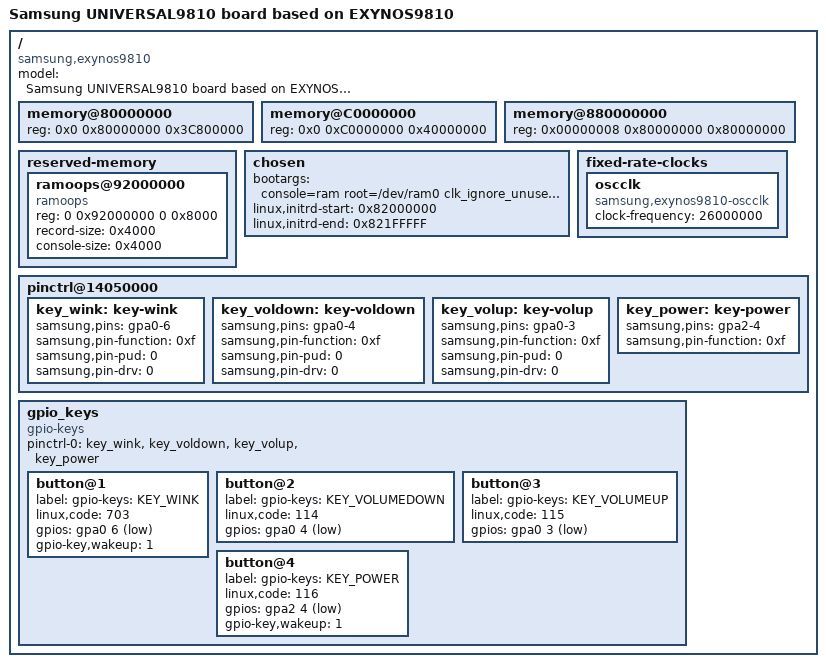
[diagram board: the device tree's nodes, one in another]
/*
 * SAMSUNG EXYNOS9810 board device tree source
 *
 * Copyright (c) 2017 Samsung Electronics Co., Ltd.
 *		http://www.samsung.com
 *
 * This program is free software; you can redistribute it and/or modify
 * it under the terms of the GNU General Public License version 2 as
 * published by the Free Software Foundation.
*/

#include "exynos9810.dtsi"

/ {
	model = "Samsung UNIVERSAL9810 board based on EXYNOS9810";
	compatible = "samsung,exynos9810", "samsung,UNIVERSAL9810";

	memory@80000000 {
		device_type = "memory";
		reg = <0x0 0x80000000 0x3C800000>;
	};

	memory@C0000000 {
		device_type = "memory";
		reg = <0x0 0xC0000000 0x40000000>;
	};

	memory@880000000 {
		device_type = "memory";
		reg = <0x00000008 0x80000000 0x80000000>;
	};

	reserved-memory {
		#address-cells = <2>;
		#size-cells = <2>;
		ranges;

		ramoops@92000000 {
			compatible = "ramoops";
			reg = <0 0x92000000 0 0x8000>;
			record-size = <0x4000>;
			console-size = <0x4000>;
		};
	};

	chosen {
		bootargs = "console=ram root=/dev/ram0 clk_ignore_unused androidboot.hardware=samsungexynos9810";
		linux,initrd-start = <0x82000000>;
		linux,initrd-end = <0x821FFFFF>;
	};

	fixed-rate-clocks {
		oscclk {
			compatible = "samsung,exynos9810-oscclk";
			clock-frequency = <26000000>;
		};
	};

	pinctrl@14050000 {
		key_wink: key-wink {
			samsung,pins = "gpa0-6";
			samsung,pin-function = <0xf>;
			samsung,pin-pud = <0>;
			samsung,pin-drv = <0>;
		};

		key_voldown: key-voldown {
			samsung,pins = "gpa0-4";
			samsung,pin-function = <0xf>;
			samsung,pin-pud = <0>;
			samsung,pin-drv = <0>;
		};

		key_volup: key-volup {
			samsung,pins = "gpa0-3";
			samsung,pin-function = <0xf>;
			samsung,pin-pud = <0>;
			samsung,pin-drv = <0>;
		};

		key_power: key-power {
			samsung,pins = "gpa2-4";
			samsung,pin-function = <0xf>;
		};
	};

	gpio_keys {
		status = "okay";
		compatible = "gpio-keys";
		#address-cells = <1>;
		#size-cells = <0>;
		pinctrl-names = "default";
		pinctrl-0 = <&key_wink &key_voldown &key_volup &key_power>;
		button@1 {
			label = "gpio-keys: KEY_WINK";
			linux,code = <703>;
			gpios = <&gpa0 6 0xf>;
			gpio-key,wakeup = <1>;
		};
		button@2 {
			label = "gpio-keys: KEY_VOLUMEDOWN";
			linux,code = <114>;
			gpios = <&gpa0 4 0xf>;
		};
		button@3 {
			label = "gpio-keys: KEY_VOLUMEUP";
			linux,code = <115>;
			gpios = <&gpa0 3 0xf>;
		};
		button@4 {
			label = "gpio-keys: KEY_POWER";
			linux,code = <116>;
			gpios = <&gpa2 4 0xf>;
			gpio-key,wakeup = <1>;
		};
	};
};
